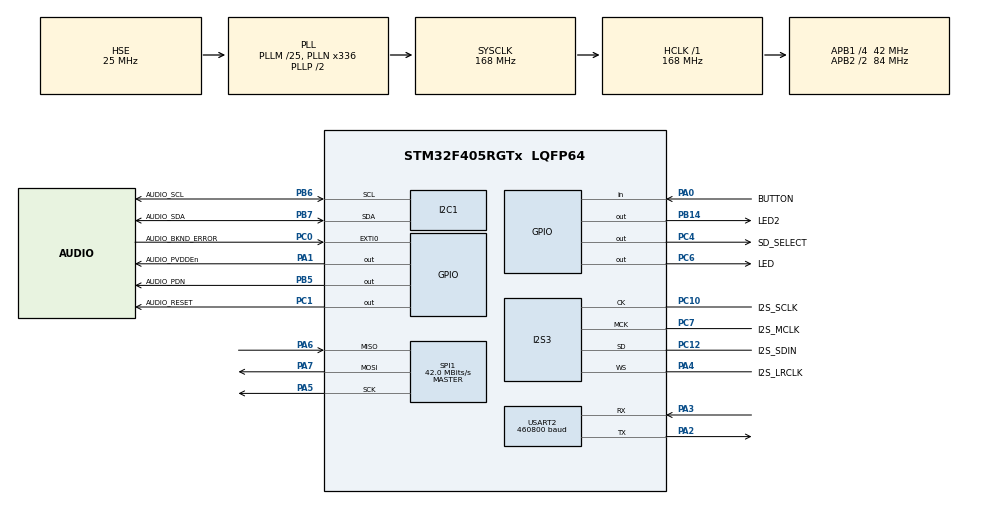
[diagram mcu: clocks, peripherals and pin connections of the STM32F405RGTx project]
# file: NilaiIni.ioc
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Dma.Request0=USART2_RX
Dma.Request1=SPI3_TX
Dma.SPI3_TX.1.Direction=DMA_MEMORY_TO_PERIPH
Dma.SPI3_TX.1.FIFOMode=DMA_FIFOMODE_DISABLE
Dma.SPI3_TX.1.Instance=DMA1_Stream7
Dma.SPI3_TX.1.MemDataAlignment=DMA_MDATAALIGN_HALFWORD
Dma.SPI3_TX.1.MemInc=DMA_MINC_ENABLE
Dma.SPI3_TX.1.Mode=DMA_CIRCULAR
Dma.SPI3_TX.1.PeriphDataAlignment=DMA_PDATAALIGN_HALFWORD
Dma.SPI3_TX.1.PeriphInc=DMA_PINC_DISABLE
Dma.SPI3_TX.1.Priority=DMA_PRIORITY_VERY_HIGH
Dma.USART2_RX.0.Direction=DMA_PERIPH_TO_MEMORY
Dma.USART2_RX.0.FIFOMode=DMA_FIFOMODE_DISABLE
Dma.USART2_RX.0.Instance=DMA1_Stream5
Dma.USART2_RX.0.MemDataAlignment=DMA_MDATAALIGN_BYTE
Dma.USART2_RX.0.MemInc=DMA_MINC_ENABLE
Dma.USART2_RX.0.Mode=DMA_NORMAL
Dma.USART2_RX.0.PeriphDataAlignment=DMA_PDATAALIGN_BYTE
Dma.USART2_RX.0.PeriphInc=DMA_PINC_DISABLE
Dma.USART2_RX.0.Priority=DMA_PRIORITY_LOW
FATFS._USE_FIND=1
FATFS._USE_LABEL=1
I2C1.I2C_Mode=I2C_Standard
I2S3.AudioFreq=I2S_AUDIOFREQ_48K
I2S3.ErrorAudioFreq=-0.01 %
I2S3.FullDuplexMode=I2S_FULLDUPLEXMODE_DISABLE
I2S3.Instance=SPI$Index
I2S3.RealAudioFreq=47.991 KHz
I2S3.Standard=I2S_STANDARD_PHILIPS
I2S3.VirtualMode=I2S_MODE_MASTER
Mcu.Family=STM32F4
Mcu.Name=STM32F405RGTx
Mcu.Package=LQFP64
NVIC.DMA1_Stream5_IRQn=true\:0\:0\:false\:false\:true\:false\:true
NVIC.DMA1_Stream7_IRQn=true\:0\:0\:false\:false\:true\:false\:true
NVIC.EXTI0_IRQn=true\:0\:0\:false\:false\:true\:true\:true
NVIC.I2C1_ER_IRQn=true\:0\:0\:false\:false\:true\:true\:true
NVIC.I2C1_EV_IRQn=true\:0\:0\:false\:false\:true\:true\:true
NVIC.PriorityGroup=NVIC_PRIORITYGROUP_4
NVIC.SPI1_IRQn=true\:0\:0\:false\:false\:true\:true\:true
NVIC.SPI3_IRQn=true\:0\:0\:false\:false\:true\:true\:true
NVIC.USART2_IRQn=true\:0\:0\:false\:false\:true\:true\:true
PA0-WKUP.GPIO_Label=BUTTON
PA0-WKUP.Signal=GPIO_Input
PA1.GPIO_Label=AUDIO_PVDDEn
PA1.Signal=GPIO_Output
PA13.Mode=Serial_Wire
PA13.Signal=SYS_JTMS-SWDIO
PA14.Mode=Serial_Wire
PA14.Signal=SYS_JTCK-SWCLK
PA2.Mode=Asynchronous
PA2.Signal=USART2_TX
PA3.Mode=Asynchronous
PA3.Signal=USART2_RX
PA4.GPIO_Label=I2S_LRCLK
PA4.Mode=Half_Duplex_Master
PA4.Signal=I2S3_WS
PA5.Mode=Full_Duplex_Master
PA5.Signal=SPI1_SCK
PA6.Mode=Full_Duplex_Master
PA6.Signal=SPI1_MISO
PA7.Mode=Full_Duplex_Master
PA7.Signal=SPI1_MOSI
PB14.GPIO_Label=LED2
PB14.Signal=GPIO_Output
PB5.GPIO_Label=AUDIO_PDN
PB5.Signal=GPIO_Output
PB6.GPIO_Label=AUDIO_SCL
PB6.Mode=I2C
PB6.Signal=I2C1_SCL
PB7.GPIO_Label=AUDIO_SDA
PB7.Mode=I2C
PB7.Signal=I2C1_SDA
PC0.GPIO_Label=AUDIO_BKND_ERROR
PC0.GPIO_ModeDefaultEXTI=GPIO_MODE_IT_FALLING
PC0.Signal=GPXTI0
PC1.GPIO_Label=AUDIO_RESET
PC1.Signal=GPIO_Output
PC10.GPIO_Label=I2S_SCLK
PC10.Mode=Half_Duplex_Master
PC10.Signal=I2S3_CK
PC12.GPIO_Label=I2S_SDIN
PC12.Mode=Half_Duplex_Master
PC12.Signal=I2S3_SD
PC4.GPIO_Label=SD_SELECT
PC4.Signal=GPIO_Output
PC6.GPIO_Label=LED
PC6.Signal=GPIO_Output
PC7.GPIO_Label=I2S_MCLK
PC7.Mode=Master_Clock_Activated
PC7.Signal=I2S3_MCK
PH0-OSC_IN.Mode=HSE-External-Oscillator
PH0-OSC_IN.Signal=RCC_OSC_IN
PH1-OSC_OUT.Mode=HSE-External-Oscillator
PH1-OSC_OUT.Signal=RCC_OSC_OUT
ProjectManager.HeapSize=0x200
ProjectManager.StackSize=0x400
ProjectManager.TargetToolchain=STM32CubeIDE
RCC.48MHZClocksFreq_Value=84000000
RCC.AHBFreq_Value=168000000
RCC.APB1CLKDivider=RCC_HCLK_DIV4
RCC.APB1Freq_Value=42000000
RCC.APB1TimFreq_Value=84000000
RCC.APB2CLKDivider=RCC_HCLK_DIV2
RCC.APB2Freq_Value=84000000
RCC.APB2TimFreq_Value=168000000
RCC.CortexFreq_Value=168000000
RCC.HCLKFreq_Value=168000000
RCC.HSE_VALUE=25000000
RCC.HSI_VALUE=16000000
RCC.LSE_VALUE=32768
RCC.PLLI2SN=258
RCC.PLLI2SR=3
RCC.PLLM=25
RCC.PLLN=336
RCC.PLLSourceVirtual=RCC_PLLSOURCE_HSE
RCC.SYSCLKFreq_VALUE=168000000
RCC.SYSCLKSource=RCC_SYSCLKSOURCE_PLLCLK
RCC.VCOOutputFreq_Value=336000000
SPI1.BaudRatePrescaler=SPI_BAUDRATEPRESCALER_2
SPI1.CalculateBaudRate=42.0 MBits/s
SPI1.Direction=SPI_DIRECTION_2LINES
SPI1.Mode=SPI_MODE_MASTER
SPI1.VirtualType=VM_MASTER
USART2.BaudRate=460800
USART2.VirtualMode=VM_ASYNC
VP_FATFS_VS_Generic.Mode=User_defined
board=custom

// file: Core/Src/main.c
/* USER CODE BEGIN Header */
/**
 ******************************************************************************
 * @file           : main.c
 * @brief          : Main program body
 ******************************************************************************
 * @attention
 *
 * <h2><center>&copy; Copyright (c) 2022 STMicroelectronics.
 * All rights reserved.</center></h2>
 *
 * This software component is licensed by ST under BSD 3-Clause license,
 * the "License"; You may not use this file except in compliance with the
 * License. You may obtain a copy of the License at:
 *                        opensource.org/licenses/BSD-3-Clause
 *
 ******************************************************************************
 */
/* USER CODE END Header */
#include "main.h"
#include "dma.h"
#include "fatfs.h"
#include "i2c.h"
#include "i2s.h"
#include "spi.h"
#include "usart.h"
#include "gpio.h"

void SystemClock_Config(void);

int main(void)
{

  /* MCU Configuration--------------------------------------------------------*/

  /* Reset of all peripherals, Initializes the Flash interface and the Systick. */
  HAL_Init();

  /* Configure the system clock */
  SystemClock_Config();

  /* Initialize all configured peripherals */
  MX_GPIO_Init();
  MX_DMA_Init();
  MX_USART2_UART_Init();
  MX_SPI1_Init();
  MX_FATFS_Init();
  MX_I2C1_Init();
  MX_I2S3_Init();
  /* USER CODE BEGIN 2 */
    HAL_UART_Transmit(&huart2, "Hello, world!", sizeof("Hello, world!"), 100);
  /* USER CODE END 2 */

  /* Infinite loop */
    while (1)
    {

    }
}

void SystemClock_Config(void)
{
  RCC_OscInitTypeDef RCC_OscInitStruct = {0};
  RCC_ClkInitTypeDef RCC_ClkInitStruct = {0};

  /** Configure the main internal regulator output voltage
  */
  __HAL_RCC_PWR_CLK_ENABLE();
  __HAL_PWR_VOLTAGESCALING_CONFIG(PWR_REGULATOR_VOLTAGE_SCALE1);
  /** Initializes the RCC Oscillators according to the specified parameters
  * in the RCC_OscInitTypeDef structure.
  */
  RCC_OscInitStruct.OscillatorType = RCC_OSCILLATORTYPE_HSE;
  RCC_OscInitStruct.HSEState = RCC_HSE_ON;
  RCC_OscInitStruct.PLL.PLLState = RCC_PLL_ON;
  RCC_OscInitStruct.PLL.PLLSource = RCC_PLLSOURCE_HSE;
  RCC_OscInitStruct.PLL.PLLM = 25;
  RCC_OscInitStruct.PLL.PLLN = 336;
  RCC_OscInitStruct.PLL.PLLP = RCC_PLLP_DIV2;
  RCC_OscInitStruct.PLL.PLLQ = 4;
  if (HAL_RCC_OscConfig(&RCC_OscInitStruct) != HAL_OK)
  {
    Error_Handler();
  }
  /** Initializes the CPU, AHB and APB buses clocks
  */
  RCC_ClkInitStruct.ClockType = RCC_CLOCKTYPE_HCLK|RCC_CLOCKTYPE_SYSCLK
                              |RCC_CLOCKTYPE_PCLK1|RCC_CLOCKTYPE_PCLK2;
  RCC_ClkInitStruct.SYSCLKSource = RCC_SYSCLKSOURCE_PLLCLK;
  RCC_ClkInitStruct.AHBCLKDivider = RCC_SYSCLK_DIV1;
  RCC_ClkInitStruct.APB1CLKDivider = RCC_HCLK_DIV4;
  RCC_ClkInitStruct.APB2CLKDivider = RCC_HCLK_DIV2;

  if (HAL_RCC_ClockConfig(&RCC_ClkInitStruct, FLASH_LATENCY_5) != HAL_OK)
  {
    Error_Handler();
  }
}

void Error_Handler(void)
{
    __disable_irq();
    while (1)
    {
    }
}

/************************ (C) COPYRIGHT STMicroelectronics *****END OF FILE****/
